AUTOSAR XML (schema 4-0-3)
package /ComponentTypes
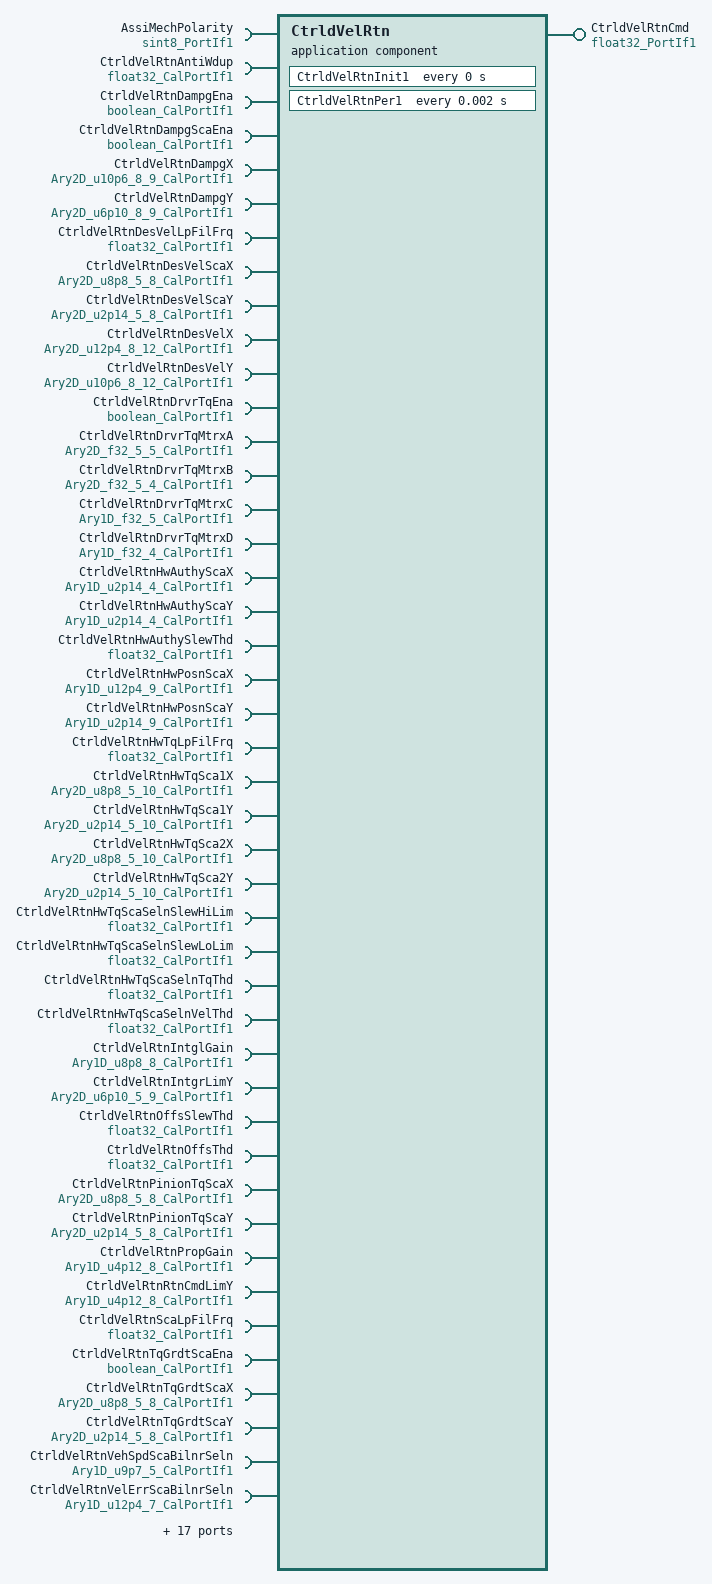
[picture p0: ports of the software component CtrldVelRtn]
  application sw component type CtrldVelRtn
    provide port CtrldVelRtnCmd: nonqueued-sender-com-spec{data-element=Val, init-value=0}, provided-interface=float32_PortIf1
    61 x require port:
      AssiMechPolarity: nonqueued-receiver-com-spec{data-element=Val, filter=data-filter-type=ALWAYS, init-value=1}, required-interface=sint8_PortIf1
      CtrldVelRtnAntiWdup: parameter-require-com-spec{init-value=1, parameter=Val}, required-interface=float32_CalPortIf1
      CtrldVelRtnDampgEna: parameter-require-com-spec{init-value=0, parameter=Logl}, required-interface=boolean_CalPortIf1
      CtrldVelRtnDampgScaEna: parameter-require-com-spec{init-value=0, parameter=Logl}, required-interface=boolean_CalPortIf1
      CtrldVelRtnDampgX: parameter-require-com-spec{init-value=[[0, 8960, 10560, 12160, 13760, 15360, 18560, 21760, 24960], [0, 8960, 10560, 12160, 13760, 15360, 18560, 21760, 24960], [0, 8960, 10560, 12160, 13760, 15360, 18560, 21760, 24960], [0, 8960, 10560, 12160, 13760, 15360, 18560, 21760, 24960], [0, 8960, 10560, 12160, 13760, 15360, 18560, 21760, 24960], [0, 16000, 17600, 19200, 20800, 22400, 25600, 28800, 32000], [0, 20608, 22208, 23808, 25408, 27008, 30208, 33408, 36608], [0, 26112, 27712, 29312, 30912, 32512, 35712, 38912, 42112]], parameter=Ary2D}, required-interface=Ary2D_u10p6_8_9_CalPortIf1
      CtrldVelRtnDampgY: parameter-require-com-spec{init-value=[9 x 0, 9 x 0, 9 x 0, 9 x 0, [0, 0, 1037, 4355, 9735, 16396, 33177, 33177, 33177], [0, 0, 1152, 4839, 10817, 18218, 36863, 36863, 36863], [0, 0, 1152, 4839, 10817, 18218, 36863, 36863, 36863], [0, 0, 1152, 4839, 10817, 18218, 36863, 36863, 36863]], parameter=Ary2D}, required-interface=Ary2D_u6p10_8_9_CalPortIf1
      CtrldVelRtnDesVelLpFilFrq: parameter-require-com-spec{init-value=20, parameter=Val}, required-interface=float32_CalPortIf1
      CtrldVelRtnDesVelScaX: parameter-require-com-spec{init-value=5 x [0, 384, 512, 640, 768, 896, 1024, 2560], parameter=Ary2D}, required-interface=Ary2D_u8p8_5_8_CalPortIf1
      CtrldVelRtnDesVelScaY: parameter-require-com-spec{init-value=5 x [16384, 16384, 16384, 16384, 0, 0, 0, 0], parameter=Ary2D}, required-interface=Ary2D_u2p14_5_8_CalPortIf1
      CtrldVelRtnDesVelX: parameter-require-com-spec{init-value=8 x [0, 261, 451, 776, 994, 1220, 1441, 1767, 7200, 7216, 7232, 7248], parameter=Ary2D}, required-interface=Ary2D_u12p4_8_12_CalPortIf1
      CtrldVelRtnDesVelY: parameter-require-com-spec{init-value=[12 x 0, [0, 1788, 3385, 5353, 6805, 8089, 8953, 9259, 9259, 9259, 9259, 9259], [0, 2446, 4630, 7323, 9309, 11066, 12247, 12666, 12666, 12666, 12666, 12666], [0, 3090, 5849, 9249, 11759, 13978, 15470, 16000, 16000, 16000, 16000, 16000], [0, 3708, 7019, 11099, 14111, 16774, 18564, 19200, 19200, 19200, 19200, 19200], [0, 5340, 10108, 15983, 20320, 24155, 26732, 27648, 27648, 27648, 27648, 27648], [0, 6408, 12130, 19180, 24384, 28986, 32078, 33178, 33178, 33178, 33178, 33178], [0, 7306, 13828, 21865, 27798, 33044, 36569, 37823, 37823, 37823, 37823, 37823]], parameter=Ary2D}, required-interface=Ary2D_u10p6_8_12_CalPortIf1
      CtrldVelRtnDrvrTqEna: parameter-require-com-spec{init-value=0, parameter=Logl}, required-interface=boolean_CalPortIf1
      CtrldVelRtnDrvrTqMtrxA: parameter-require-com-spec{init-value=[[-0.17159, 0.00010352, 1.1696, 0.00024516, 1.9834e-05], [-240.58, 0.060289, 240.53, 0.17028, 0.047148], [0.0018246, -4.2826e-06, 0.99616, 0.00025897, -2.8965e-07], [-6.1943, 0.014635, 5.9127, 0.11656, 0.00098854], [-70.875, -0.28572, 70.86, 0.053221, 0.98679]], parameter=Ary2D}, required-interface=Ary2D_f32_5_5_CalPortIf1
      CtrldVelRtnDrvrTqMtrxB: parameter-require-com-spec{init-value=[[3.2994e-07, 0.0081464, 0.0019034, 0.0016485], [0.00045434, 1.6329, 0.0015119, 0.76734], [1.1488e-06, -2.4566e-05, 0.0019002, 0.001743], [0.0027499, 0.045004, 0.00025007, 0.86756], [0.0001448, 0.50816, -2.5948e-05, 0.23299]], parameter=Ary2D}, required-interface=Ary2D_f32_5_4_CalPortIf1
      CtrldVelRtnDrvrTqMtrxC: parameter-require-com-spec{init-value=[0, 0, 0, 0, 1], parameter=Ary1D}, required-interface=Ary1D_f32_5_CalPortIf1
      CtrldVelRtnDrvrTqMtrxD: parameter-require-com-spec{init-value=[0, 0, 0, 0], parameter=Ary1D}, required-interface=Ary1D_f32_4_CalPortIf1
      CtrldVelRtnHwAuthyScaX: parameter-require-com-spec{init-value=[0, 8192, 12288, 16384], parameter=Ary1D}, required-interface=Ary1D_u2p14_4_CalPortIf1
      CtrldVelRtnHwAuthyScaY: parameter-require-com-spec{init-value=[0, 0, 0, 16384], parameter=Ary1D}, required-interface=Ary1D_u2p14_4_CalPortIf1
      CtrldVelRtnHwAuthySlewThd: parameter-require-com-spec{init-value=0.5, parameter=Val}, required-interface=float32_CalPortIf1
      CtrldVelRtnHwPosnScaX: parameter-require-com-spec{init-value=[0, 160, 320, 640, 656, 1440, 2880, 5760, 16000], parameter=Ary1D}, required-interface=Ary1D_u12p4_9_CalPortIf1
      CtrldVelRtnHwPosnScaY: parameter-require-com-spec{init-value=9 x 16384, parameter=Ary1D}, required-interface=Ary1D_u2p14_9_CalPortIf1
      CtrldVelRtnHwTqLpFilFrq: parameter-require-com-spec{init-value=20, parameter=Val}, required-interface=float32_CalPortIf1
      CtrldVelRtnHwTqSca1X: parameter-require-com-spec{init-value=5 x [0, 102, 128, 154, 182, 337, 412, 521, 640, 2048], parameter=Ary2D}, required-interface=Ary2D_u8p8_5_10_CalPortIf1
      CtrldVelRtnHwTqSca1Y: parameter-require-com-spec{init-value=5 x [16384, 16384, 16071, 15540, 14495, 9349, 6704, 3116, 0, 0], parameter=Ary2D}, required-interface=Ary2D_u2p14_5_10_CalPortIf1
      CtrldVelRtnHwTqSca2X: parameter-require-com-spec{init-value=5 x [0, 102, 128, 154, 182, 337, 412, 521, 640, 2048], parameter=Ary2D}, required-interface=Ary2D_u8p8_5_10_CalPortIf1
      CtrldVelRtnHwTqSca2Y: parameter-require-com-spec{init-value=5 x [16384, 16384, 16071, 15540, 14495, 9349, 6704, 3116, 0, 0], parameter=Ary2D}, required-interface=Ary2D_u2p14_5_10_CalPortIf1
      CtrldVelRtnHwTqScaSelnSlewHiLim: parameter-require-com-spec{init-value=500, parameter=Val}, required-interface=float32_CalPortIf1
      CtrldVelRtnHwTqScaSelnSlewLoLim: parameter-require-com-spec{init-value=-500, parameter=Val}, required-interface=float32_CalPortIf1
      CtrldVelRtnHwTqScaSelnTqThd: parameter-require-com-spec{init-value=0, parameter=Val}, required-interface=float32_CalPortIf1
      CtrldVelRtnHwTqScaSelnVelThd: parameter-require-com-spec{init-value=0, parameter=Val}, required-interface=float32_CalPortIf1
      CtrldVelRtnIntglGain: parameter-require-com-spec{init-value=[0, 38, 38, 51, 64, 64, 64, 64], parameter=Ary1D}, required-interface=Ary1D_u8p8_8_CalPortIf1
      CtrldVelRtnIntgrLimY: parameter-require-com-spec{init-value=[[2048, 5120, 5120, 10240, 10240, 15360, 15360, 20480, 20480], [2048, 5120, 5120, 10240, 10240, 15360, 15360, 20480, 20480], [2048, 5120, 5120, 10240, 10240, 10240, 15360, 15360, 15360], [2048, 5120, 5120, 10240, 10240, 10240, 10240, 10240, 10240], [2048, 5120, 5120, 10240, 10240, 10240, 10240, 10240, 10240]], parameter=Ary2D}, required-interface=Ary2D_u6p10_5_9_CalPortIf1
      CtrldVelRtnOffsSlewThd: parameter-require-com-spec{init-value=0.04, parameter=Val}, required-interface=float32_CalPortIf1
      CtrldVelRtnOffsThd: parameter-require-com-spec{init-value=17, parameter=Val}, required-interface=float32_CalPortIf1
      CtrldVelRtnPinionTqScaX: parameter-require-com-spec{init-value=5 x [0, 384, 512, 640, 768, 896, 1024, 2560], parameter=Ary2D}, required-interface=Ary2D_u8p8_5_8_CalPortIf1
      CtrldVelRtnPinionTqScaY: parameter-require-com-spec{init-value=[[16384, 16384, 16384, 9830, 0, 0, 0, 0], [16384, 16384, 16384, 9830, 0, 0, 0, 0], [16384, 16384, 16384, 9830, 0, 0, 0, 0], 8 x 16384, 8 x 16384], parameter=Ary2D}, required-interface=Ary2D_u2p14_5_8_CalPortIf1
      CtrldVelRtnPropGain: parameter-require-com-spec{init-value=[0, 82, 82, 205, 492, 492, 492, 492], parameter=Ary1D}, required-interface=Ary1D_u4p12_8_CalPortIf1
      CtrldVelRtnRtnCmdLimY: parameter-require-com-spec{init-value=8 x 16384, parameter=Ary1D}, required-interface=Ary1D_u4p12_8_CalPortIf1
      CtrldVelRtnScaLpFilFrq: parameter-require-com-spec{init-value=20, parameter=Val}, required-interface=float32_CalPortIf1
      CtrldVelRtnTqGrdtScaEna: parameter-require-com-spec{init-value=0, parameter=Logl}, required-interface=boolean_CalPortIf1
      CtrldVelRtnTqGrdtScaX: parameter-require-com-spec{init-value=5 x [0, 5120, 6400, 7680, 8960, 10240, 11520, 12800], parameter=Ary2D}, required-interface=Ary2D_u8p8_5_8_CalPortIf1
      CtrldVelRtnTqGrdtScaY: parameter-require-com-spec{init-value=[[16384, 16384, 13107, 8192, 4915, 4915, 4915, 4915], [16384, 16384, 13107, 8192, 4915, 4915, 4915, 4915], [16384, 16384, 13107, 8192, 4915, 4915, 4915, 4915], [16384, 16384, 13107, 11469, 6554, 6554, 6554, 6554], [16384, 16384, 13107, 11469, 6554, 6554, 6554, 6554]], parameter=Ary2D}, required-interface=Ary2D_u2p14_5_8_CalPortIf1
      CtrldVelRtnVehSpdScaBilnrSeln: parameter-require-com-spec{init-value=[0, 1280, 3840, 6400, 10240], parameter=Ary1D}, required-interface=Ary1D_u9p7_5_CalPortIf1
      CtrldVelRtnVelErrScaBilnrSeln: parameter-require-com-spec{init-value=[0, 160, 320, 480, 800, 1280, 7200], parameter=Ary1D}, required-interface=Ary1D_u12p4_7_CalPortIf1
      CtrldVelRtnVelErrScaEna: parameter-require-com-spec{init-value=0, parameter=Logl}, required-interface=boolean_CalPortIf1
      CtrldVelRtnVelErrScaX: parameter-require-com-spec{init-value=[-6400, 0, 640, 1600, 3200, 6400, 8000, 25600], parameter=Ary1D}, required-interface=Ary1D_s10p5_8_CalPortIf1
      CtrldVelRtnVelErrScaY: parameter-require-com-spec{init-value=[8 x 16384, [16384, 16384, 13107, 8192, 4915, 8192, 11469, 16384], [16384, 16384, 13107, 8192, 4915, 4915, 8192, 16384], [16384, 16384, 13107, 8192, 4915, 4915, 8192, 16384], [16384, 16384, 13107, 13107, 8192, 8192, 8192, 16384], 8 x 16384, 8 x 16384], parameter=Ary2D}, required-interface=Ary2D_u2p14_7_8_CalPortIf1
      CtrldVelRtnVelErrVehSpdScaY: parameter-require-com-spec{init-value=[16384, 16384, 16384, 11469, 11469], parameter=Ary1D}, required-interface=Ary1D_u2p14_5_CalPortIf1
      CtrldVelRtnVelSpdTbl: parameter-require-com-spec{init-value=[0, 320, 640, 2560, 3840, 6400, 7680, 10240], parameter=Ary1D}, required-interface=Ary1D_u9p7_8_CalPortIf1
      HwAg: nonqueued-receiver-com-spec{data-element=Val, filter=data-filter-type=ALWAYS, init-value=0}, required-interface=float32_PortIf1
      HwAgAuthy: nonqueued-receiver-com-spec{data-element=Val, filter=data-filter-type=ALWAYS, init-value=0}, required-interface=float32_PortIf1
      HwAgRtnOffs: nonqueued-receiver-com-spec{data-element=Val, filter=data-filter-type=ALWAYS, init-value=0}, required-interface=float32_PortIf1
      HwTq: nonqueued-receiver-com-spec{data-element=Val, filter=data-filter-type=ALWAYS, init-value=0}, required-interface=float32_PortIf1
      HwVel: nonqueued-receiver-com-spec{data-element=Val, filter=data-filter-type=ALWAYS, init-value=0}, required-interface=float32_PortIf1
      MotTqCmdPwrLimd: nonqueued-receiver-com-spec{data-element=Val, filter=data-filter-type=ALWAYS, init-value=0}, required-interface=float32_PortIf1
      RtnCmdDi: nonqueued-receiver-com-spec{data-element=Logl, filter=data-filter-type=ALWAYS, init-value=0}, required-interface=boolean_PortIf1
      RtnCmdDiagcDi: nonqueued-receiver-com-spec{data-element=Logl, filter=data-filter-type=ALWAYS, init-value=0}, required-interface=boolean_PortIf1
      RtnCmdSca: nonqueued-receiver-com-spec{data-element=Val, filter=data-filter-type=ALWAYS, init-value=1}, required-interface=float32_PortIf1
      RtnCmdScaServo: nonqueued-receiver-com-spec{data-element=Val, filter=data-filter-type=ALWAYS, init-value=1}, required-interface=float32_PortIf1
      SysGlbPrmSysTqRat: parameter-require-com-spec{init-value=20, parameter=Val}, required-interface=float32_CalPortIf1
      VehSpd: nonqueued-receiver-com-spec{data-element=Val, filter=data-filter-type=ALWAYS, init-value=0}, required-interface=float32_PortIf1
    behavior CtrldVelRtn_InternalBehavior
      ar-typed-per-instance-memorys:
        41 x data, all with sw-calibration-access=READ-ONLY:
          CtrlScaLpFil: type=FilLpRec1
          dCtrldVelRtnCtrlSca: type=float32
          dCtrldVelRtnCtrlScaPreFild: type=float32
          dCtrldVelRtnDampgCmd: type=float32
          dCtrldVelRtnDesVel: type=float32
          dCtrldVelRtnDesVelSca: type=float32
          dCtrldVelRtnDesVelScaPreFild: type=float32
          dCtrldVelRtnDrvrTqEstimd: type=float32
          dCtrldVelRtnDrvrTqFild: type=float32
          dCtrldVelRtnHwAgCmp: type=float32
          dCtrldVelRtnHwAuthySca: type=float32
          dCtrldVelRtnHwPosnSca: type=float32
          dCtrldVelRtnHwTqSca: type=float32
          dCtrldVelRtnHwTqScaSeln: type=float32
          dCtrldVelRtnIntglTermCmd: type=float32
          dCtrldVelRtnIntgrLim: type=float32
          dCtrldVelRtnPinionTqSca: type=float32
          dCtrldVelRtnPropTermCmd: type=float32
          dCtrldVelRtnRtnCmd: type=float32
          dCtrldVelRtnRtnCmdPreLim: type=float32
          dCtrldVelRtnTqGrdt: type=float32
          dCtrldVelRtnTqGrdtSca: type=float32
          dCtrldVelRtnVelErrSca: type=float32
          DesVelLpFil: type=FilLpRec1
          DesVelScaLpFil: type=FilLpRec1
          DrvrTqLpFil: type=FilLpRec1
          PinionTqLpFil: type=FilLpRec1
          PrevDesVel: type=float32
          PrevDrvrTqFildA: type=float32
          PrevDrvrTqFildB: type=float32
          PrevDrvrTqFildC: type=float32
          PrevDrvrTqFildD: type=float32
          PrevDrvrTqFildE: type=float32
          PrevDrvrTqFildF: type=float32
          PrevDrvrTqMtrx: type=Ary1D_f32_5
          PrevHwAuthySca: type=float32
          PrevHwTqSeln: type=float32
          PrevIntglTermA: type=float32
          PrevIntglTermB: type=float32
          PrevIntglTermC: type=float32
          PrevRtnOffs: type=float32
      timing event CtrldVelRtn_InitEvent: start-on-event=CtrldVelRtnInit1, period=0
      timing event TMT_CtrldVelRtnPer1: start-on-event=CtrldVelRtnPer1, period=0.002
      runnable CtrldVelRtnInit1
      runnable CtrldVelRtnPer1
        data-receive-point-by-arguments:
          12 x access:
            REC_AssiMechPolarity_Val: accessed-variable=AssiMechPolarity.Val
            REC_HwAg_Val: accessed-variable=HwAg.Val
            REC_HwAgAuthy_Val: accessed-variable=HwAgAuthy.Val
            REC_HwAgRtnOffs_Val: accessed-variable=HwAgRtnOffs.Val
            REC_HwTq_Val: accessed-variable=HwTq.Val
            REC_HwVel_Val: accessed-variable=HwVel.Val
            REC_MotTqCmdPwrLimd_Val: accessed-variable=MotTqCmdPwrLimd.Val
            REC_RtnCmdDi_Logl: accessed-variable=RtnCmdDi.Logl
            REC_RtnCmdDiagcDi_Logl: accessed-variable=RtnCmdDiagcDi.Logl
            REC_RtnCmdSca_Val: accessed-variable=RtnCmdSca.Val
            REC_RtnCmdScaServo_Val: accessed-variable=RtnCmdScaServo.Val
            REC_VehSpd_Val: accessed-variable=VehSpd.Val
        data-send-points:
          access SEND_RtnCmd_Val: accessed-variable=CtrldVelRtnCmd.Val
  swc implementation CtrldVelRtn_Implementation: behavior=CtrldVelRtn_InternalBehavior
    code-descriptors:
      code Default: artifact-descriptors=autosar-engineering-object={short-label=Default, category=SWSRC}
